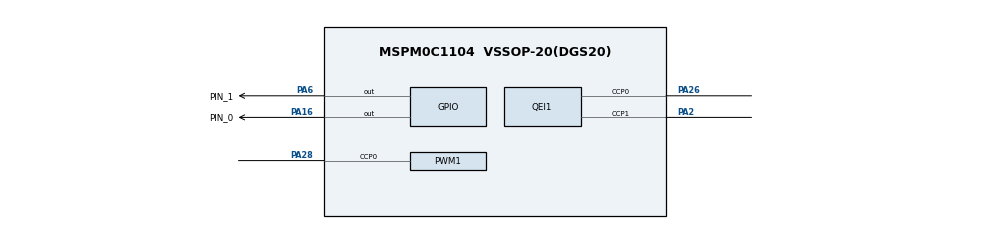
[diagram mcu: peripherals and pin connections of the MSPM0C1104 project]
//@cliArgs --device "MSPM0C110X" --package "VSSOP-20(DGS20)" --part "Default"
//@v2CliArgs --device "MSPM0C1104" --package "VSSOP-20(DGS20)"
// @cliArgs --board /ti/boards/LP_MSPM0C1104 --rtos nortos

/**
 * Import the modules used in this configuration.
 */
const ADC12  = scripting.addModule("/ti/driverlib/ADC12", {}, false);
const ADC121 = ADC12.addInstance();
const GPIO   = scripting.addModule("/ti/driverlib/GPIO", {}, false);
const GPIO1  = GPIO.addInstance();
const GPIO2  = GPIO.addInstance();
const PWM    = scripting.addModule("/ti/driverlib/PWM", {}, false);
const PWM1   = PWM.addInstance();
const QEI    = scripting.addModule("/ti/driverlib/QEI", {}, false);
const QEI1   = QEI.addInstance();
const SYSCTL = scripting.addModule("/ti/driverlib/SYSCTL");
const TIMER  = scripting.addModule("/ti/driverlib/TIMER", {}, false);
const TIMER1 = TIMER.addInstance();

/**
 * Write custom configuration values to the imported modules.
 */
ADC121.$name                      = "ADC12_0";
ADC121.sampleTime0                = "125us";
ADC121.adcMem0avgen               = true;
ADC121.hwNumerator                = "DL_ADC12_HW_AVG_NUM_ACC_64";
ADC121.hwDenominator              = "DL_ADC12_HW_AVG_DEN_DIV_BY_64";
ADC121.peripheral.$assign         = "ADC0";
ADC121.peripheral.adcPin0.$assign = "PA27";

const Board = scripting.addModule("/ti/driverlib/Board", {}, false);

GPIO1.$name                          = "GPIO_GRP_0";
GPIO1.associatedPins[0].$name        = "PIN_0";
GPIO1.associatedPins[0].initialValue = "SET";
GPIO1.associatedPins[0].pin.$assign  = "PA16";

GPIO2.$name                         = "GPIO_GRP_1";
GPIO2.associatedPins[0].$name       = "PIN_1";
GPIO2.associatedPins[0].pin.$assign = "PA6";

PWM1.$name                           = "PWM_0";
PWM1.timerStartTimer                 = true;
PWM1.pwmMode                         = "CENTER_ALIGN";
PWM1.ccIndexCmpl                     = [0,1];
PWM1.deadBandEn                      = true;
PWM1.dbRiseDelayTimerCount           = 25;
PWM1.dbFallDelayTimerCount           = 25;
PWM1.ccIndex                         = [0];
PWM1.peripheral.$assign              = "TIMA0";
PWM1.peripheral.ccp0Pin.$assign      = "PA28";
PWM1.peripheral.ccp0Pin_cmpl.$assign = "PA4";
PWM1.PWM_CHANNEL_0.$name             = "ti_driverlib_pwm_PWMTimerCC0";
PWM1.PWM_CHANNEL_0.ccValue           = 500;

QEI1.$name                      = "QEI_0";
QEI1.timerStartTimer            = true;
QEI1.peripheral.$assign         = "TIMG8";
QEI1.peripheral.ccp0Pin.$assign = "PA26";
QEI1.peripheral.ccp1Pin.$assign = "PA2";

TIMER1.$name            = "TIMER_0";
TIMER1.timerMode        = "PERIODIC";
TIMER1.interrupts       = ["ZERO"];
TIMER1.timerStartTimer  = true;
TIMER1.timerClkPrescale = 100;
TIMER1.timerPeriod      = "50ms";
